# WKUP_CTRL_MMR_WKUP_CTRL_MMR_CFG0_43000000h register map
Vendor: Texas Instruments
Registers are 32-bit, read-write, reset 0x0 unless marked. A register's access mark holds for its fields unless they carry their own. Offsets are as the file gives them; [hi:lo] are bit positions; {n}, {i} and the like mark numbered series.

## WKUP_CTRL_MMR_CFG0 (part 3 of 3)
0x18440 WKUP_CTRL_MMR_CFG0_DS_DM_RESET reset 0xF
  [3:0] DS_DM_RESET_MASK — Signal used to mask main domain resets from Device Manager / Wakeup and MCU IpsField values (others are reserved):4'b0110 - Masked4'b1111 - UnMasked Reset Source: mcu_chip1_rst_n
0x18460 WKUP_CTRL_MMR_CFG0_DS_USB0_RESET reset 0xF
  [3:0] DS_USB0_RESET_MASK — Signal used to block reset to the USBSS0Field values (others are reserved):4'b0110 - Masked4'b1111 - UnMasked Reset Source: mcu_chip1_rst_n
0x18464 WKUP_CTRL_MMR_CFG0_DS_USB1_RESET reset 0xF
  [3:0] DS_USB1_RESET_MASK — Signal used to block reset to the USBSS1Field values (others are reserved):4'b0110 - Masked4'b1111 - UnMasked Reset Source: mcu_chip1_rst_n
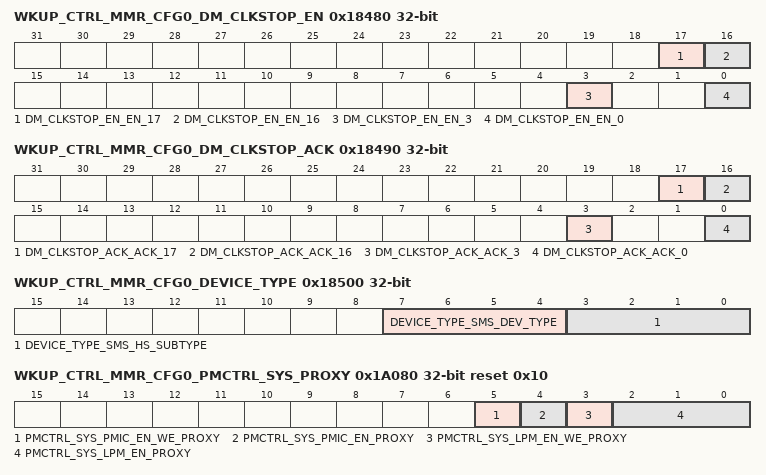
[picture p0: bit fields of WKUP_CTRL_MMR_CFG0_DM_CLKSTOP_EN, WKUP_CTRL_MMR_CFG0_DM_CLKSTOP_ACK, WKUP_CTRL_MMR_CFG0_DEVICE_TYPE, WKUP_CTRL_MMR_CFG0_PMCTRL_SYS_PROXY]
0x18480 WKUP_CTRL_MMR_CFG0_DM_CLKSTOP_EN
  [17] DM_CLKSTOP_EN_EN_17 — WKUP DMTIMER1 Participation in Clockstop Req GroupField values (others are reserved):1'b0 - Not Participating in Clockstop Override Group. DM_CLKSTOP_ACK.17 always reads '1'1'b1 - Participating in Clockstop Override Group. DM_CLKSTOP_ACK.17 reflects the IP clockstop_ack Reset Source: mod_por_rst_n
  [16] DM_CLKSTOP_EN_EN_16 — WKUP DMTIMER0 Participation in Clockstop Req GroupField values (others are reserved):1'b0 - Not Participating in Clockstop Override Group. DM_CLKSTOP_ACK.16 always reads '1'1'b1 - Participating in Clockstop Override Group. DM_CLKSTOP_ACK.16 reflects the IP clockstop_ack Reset Source: mod_por_rst_n
  [3] DM_CLKSTOP_EN_EN_3 — WKUP UART0 Participation in Clockstop Req GroupField values (others are reserved):1'b0 - Not Participating in Clockstop Override Group. DM_CLKSTOP_ACK.3 always reads '1'1'b1 - Participating in Clockstop Override Group. DM_CLKSTOP_ACK.3 reflects the IP clockstop_ack Reset Source: mod_por_rst_n
  [0] DM_CLKSTOP_EN_EN_0 — WKUP I2C0 Participation in Clockstop Req GroupField values (others are reserved):1'b0 - Not Participating in Clockstop Override Group. DM_CLKSTOP_ACK.0 always reads '1'1'b1 - Participating in Clockstop Override Group. DM_CLKSTOP_ACK.0 reflects the IP clockstop_ack Reset Source: mod_por_rst_n
0x18490 WKUP_CTRL_MMR_CFG0_DM_CLKSTOP_ACK ro
  [17] DM_CLKSTOP_ACK_ACK_17 — WKUP DMTIMER1 Clockstop Ack StatusField values (others are reserved):1'b0 - IP is Participating in Clockstop Override Group, and IP clockstop_ack is 01'b1 - IP Is either not Participating in Clockstop Override Group, or IP has returned IP clockstop_ack Reset Source: mod_por_rst_n
  [16] DM_CLKSTOP_ACK_ACK_16 — WKUP DMTIMER0 Clockstop Ack StatusField values (others are reserved):1'b0 - IP is Participating in Clockstop Override Group, and IP clockstop_ack is 01'b1 - IP Is either not Participating in Clockstop Override Group, or IP has returned IP clockstop_ack Reset Source: mod_por_rst_n
  [3] DM_CLKSTOP_ACK_ACK_3 — WKUP UART0 Clockstop Ack StatusField values (others are reserved):1'b0 - IP is Participating in Clockstop Override Group, and IP clockstop_ack is 01'b1 - IP Is either not Participating in Clockstop Override Group, or IP has returned IP clockstop_ack Reset Source: mod_por_rst_n
  [0] DM_CLKSTOP_ACK_ACK_0 — WKUP I2C0 Clockstop Ack StatusField values (others are reserved):1'b0 - IP is Participating in Clockstop Override Group, and IP clockstop_ack is 01'b1 - IP Is either not Participating in Clockstop Override Group, or IP has returned IP clockstop_ack Reset Source: mod_por_rst_n
0x184A0 WKUP_CTRL_MMR_CFG0_DM_GRP_CLKSTOP_REQ
  [0] DM_GRP_CLKSTOP_REQ_REQ — Assertion of Clockstop Req to IPs participating in Clockstop Req GroupField values (others are reserved):1'b0 - Deassert CLKSTOP Req to all IPs participating in Clockstop Override Group1'b1 - Assert CLKSTOP Req to all IPs participating in Clockstop Override Group Reset Source: mod_por_rst_n
0x184A4 WKUP_CTRL_MMR_CFG0_DM_GRP_CLKSTOP_ACK ro
  [0] DM_GRP_CLKSTOP_ACK_ACK — Status of IPs Participating in Clockstop Ack Group. If DM_CLKSTOP_EN is 0 (no IPs participating) this bit always reads 1.Field values (others are reserved):1'b0 - At least one IP participating in Clockstop Override has not returned Ack1'b1 - All IPs that are participating in Clockstop Override have returned Ack Reset Source: mod_por_rst_n
0x18500 WKUP_CTRL_MMR_CFG0_DEVICE_TYPE ro
  [7:4] DEVICE_TYPE_SMS_DEV_TYPE — Reset Source: mod_por_rst_n
  [3:0] DEVICE_TYPE_SMS_HS_SUBTYPE — this field is not needed and inputs should be tied off on AM62. Reset Source: mod_por_rst_n
{0x19100+4i} WKUP_CTRL_MMR_CFG0_CLAIMREG_P6_R{i}_READONLY ro (i=0..10)
  [31:0] CLAIMREG_P6_R{i}_READONLY — Claim bits for Partition 6 Reset Source: mod_g_rst_n
0x1A040 WKUP_CTRL_MMR_CFG0_FW_CTRL_OUT0_PROXY
  [31:0] FW_CTRL_OUT0_FW_CTRL_OUT0_PROXY — Reset Source: mod_g_rst_n
0x1A044 WKUP_CTRL_MMR_CFG0_FW_CTRL_OUT0_SET_PROXY access not given
  [31:0] FW_CTRL_OUT0_SET_FW_CTRL_OUT0_PROXY — reserved Reset Source: mod_g_rst_n (access R/W1TS)
0x1A048 WKUP_CTRL_MMR_CFG0_FW_CTRL_OUT0_CLR_PROXY access not given
  [31:0] FW_CTRL_OUT0_CLR_FW_CTRL_OUT0_PROXY — reserved Reset Source: mod_g_rst_n (access R/W1TC)
0x1A04C WKUP_CTRL_MMR_CFG0_FW_STS_IN0_PROXY ro
  [31:0] FW_STS_IN0_EVENT_PROXY — Reserved Reset Source: mod_g_rst_n
0x1A050 WKUP_CTRL_MMR_CFG0_FW_CTRL_OUT1_PROXY
  [31:0] FW_CTRL_OUT1_FW_CTRL_OUT1_PROXY — reserved Reset Source: mod_g_rst_n
0x1A054 WKUP_CTRL_MMR_CFG0_FW_CTRL_OUT1_SET_PROXY access not given
  [31:0] FW_CTRL_OUT1_SET_FW_CTRL_OUT1_PROXY — reserved Reset Source: mod_g_rst_n (access R/W1TS)
0x1A058 WKUP_CTRL_MMR_CFG0_FW_CTRL_OUT1_CLR_PROXY access not given
  [31:0] FW_CTRL_OUT1_CLR_FW_CTRL_OUT1_PROXY — reserved Reset Source: mod_g_rst_n (access R/W1TC)
0x1A05C WKUP_CTRL_MMR_CFG0_FW_STS_IN1_PROXY ro
  [31:0] FW_STS_IN1_EVENT_PROXY — Reserved Reset Source: mod_g_rst_n
0x1A080 WKUP_CTRL_MMR_CFG0_PMCTRL_SYS_PROXY reset 0x10
  [5] PMCTRL_SYS_PMIC_EN_WE_PROXY — Unused Field - Value is Don't Care Reset Source: mod_g_rst_n
  [4] PMCTRL_SYS_PMIC_EN_PROXY — Controls state of PMIC_LPM_EN_OUT when LPM_EN[2:0] is 000 Reset Source: mod_g_rst_n
  [3] PMCTRL_SYS_LPM_EN_WE_PROXY — Unused Field - Value is Don't Care Reset Source: mod_g_rst_n
  [2:0] PMCTRL_SYS_LPM_EN_PROXY — Controls whether PMIC_LPM_EN_OUT is driven by the pmic_en bit, or by deep sleep logic. Field values (others are reserved):3'b000 - PMIC_LPM_EN_OUT controlled by pmic_en bit.3'b101 - PMIC_LPM_EN_OUT controlled by DeepSleep Logic Reset Source: mod_g_rst_n
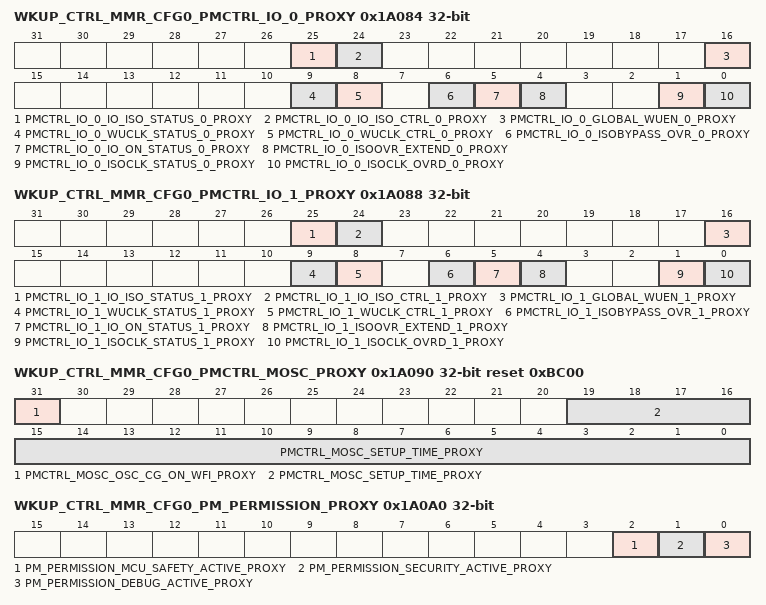
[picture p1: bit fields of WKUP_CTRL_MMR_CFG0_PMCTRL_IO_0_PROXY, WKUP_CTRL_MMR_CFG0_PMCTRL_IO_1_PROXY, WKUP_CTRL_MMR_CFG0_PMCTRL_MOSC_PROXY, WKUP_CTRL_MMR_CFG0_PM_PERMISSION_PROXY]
0x1A084 WKUP_CTRL_MMR_CFG0_PMCTRL_IO_0_PROXY access per field
  [25] PMCTRL_IO_0_IO_ISO_STATUS_0_PROXY ro — IO ISO Status. Read 0: IO isolation not active. Read 1: IO isolation active.Reflects value of DM input port io_isoack coming back fromIO pad ring. Reset Source: mod_g_rst_n
  [24] PMCTRL_IO_0_IO_ISO_CTRL_0_PROXY rw — IO ISO control. Writing this bit to 1 will kick off IO isolation. Reset Source: mod_g_rst_n
  [16] PMCTRL_IO_0_GLOBAL_WUEN_0_PROXY rw — Global IO wakeup activate. This is a gating condition to allindividual IO WUEN coming from control module. Gating isdone in the Spinner logic. 0:All individual IO WUEN are gatedin the Spinner logic (override to 0). 1: All individual IO WUENfrom control module are going to Ios.Map to DM input port io_globalwkupen Reset Source: mod_g_rst_n
  [9] PMCTRL_IO_0_WUCLK_STATUS_0_PROXY ro — Reflects value of DM input port io_wuclkack coming backfrom IO pad ring. Reset Source: mod_g_rst_n
  [8] PMCTRL_IO_0_WUCLK_CTRL_0_PROXY rw — Direct control on WUCLKIN signal to IO pad ring.0:WUCLKINsignal is driven to 0.IO wakeup daisy chain is functional as wellas IO whose wakeup feature is activated. 1:WUCLKIN signal is driven to 1. IO wakeup daisy chain is reset and is latching current pad states and WUEN inputs. Reset Source: mod_g_rst_n
  [6] PMCTRL_IO_0_ISOBYPASS_OVR_0_PROXY rw — This MMR bit drives directly DM output port io_isobypassundefined. Reset Source: mod_g_rst_n
  [5] PMCTRL_IO_0_IO_ON_STATUS_0_PROXY ro — Gives the functional status of the IO ring. Read 0: Part or all ofthe Ios are not in the ON state that is are in isolation state.Read 1: All Ios are in the ON state.io_on_status = assign 1 if (io_iso == 0 & io_isoack==0 &io_iso_clk == 0 & io_isoclk_ack = 0 ) else 0; Reset Source: mod_g_rst_n
  [4] PMCTRL_IO_0_ISOOVR_EXTEND_0_PROXY rw — This drives the SOC chain ISO-OVERRIDE global control.This bit drives directly the DM output port io_isoovrundefined. Atthe SOC level it is used to activate when 1 or gate-off when 0,the individual ISOOR for each IO. This operates as a globalactivate/deactivate for the individual IOs.Control for IO isolation extension.'0' IO isolation is not extended. Transition happens as soon asautomatic restore is completed.'1' IO isolation is extended. The IOs whose ISOOVR bits havebeen individually set in their PADCFG MMRs will all get its IOisolation extended beyond the point when the initial IO daisychain isolation is released. Reset Source: mod_g_rst_n
  [1] PMCTRL_IO_0_ISOCLK_STATUS_0_PROXY ro — Reflects value of DM input port io_isoclkack coming backfrom IO pad ring. Reset Source: mod_g_rst_n
  [0] PMCTRL_IO_0_ISOCLK_OVRD_0_PROXY rw — Override control on ISOCLKIN signal to IO pad ring.When not overridden this signal is controlled by hardware only.0 ISOCLKIN signal is not override.1 ISOCLKIN signal is overridden to active value ('1'). Reset Source: mod_g_rst_n
0x1A088 WKUP_CTRL_MMR_CFG0_PMCTRL_IO_1_PROXY access per field
  [25] PMCTRL_IO_1_IO_ISO_STATUS_1_PROXY ro — IO ISO Status. Read 0: IO isolation not active. Read 1: IO isolation active.Reflects value of DM input port io_isoack coming back fromIO pad ring. Reset Source: mod_g_rst_n
  [24] PMCTRL_IO_1_IO_ISO_CTRL_1_PROXY rw — IO ISO control. Writing this bit to 1 will kick off IO isolation. Reset Source: mod_g_rst_n
  [16] PMCTRL_IO_1_GLOBAL_WUEN_1_PROXY rw — Global IO wakeup activate. This is a gating condition to allindividual IO WUEN coming from control module. Gating isdone in the Spinner logic. 0:All individual IO WUEN are gatedin the Spinner logic (override to 0). 1: All individual IO WUENfrom control module are going to Ios.Map to DM input port io_globalwkupen Reset Source: mod_g_rst_n
  [9] PMCTRL_IO_1_WUCLK_STATUS_1_PROXY ro — Reflects value of DM input port io_wuclkack coming backfrom IO pad ring. Reset Source: mod_g_rst_n
  [8] PMCTRL_IO_1_WUCLK_CTRL_1_PROXY rw — Direct control on WUCLKIN signal to IO pad ring.0:WUCLKINsignal is driven to 0.IO wakeup daisy chain is functional as wellas IO whose wakeup feature is activated. 1:WUCLKIN signal is driven to 1. IO wakeup daisy chain is reset and is latching current pad states and WUEN inputs. Reset Source: mod_g_rst_n
  [6] PMCTRL_IO_1_ISOBYPASS_OVR_1_PROXY rw — This MMR bit drives directly DM output port io_isobypassundefined. Reset Source: mod_g_rst_n
  [5] PMCTRL_IO_1_IO_ON_STATUS_1_PROXY ro — Gives the functional status of the IO ring. Read 0: Part or all ofthe Ios are not in the ON state that is are in isolation state.Read 1: All Ios are in the ON state.io_on_status = assign 1 if (io_iso == 0 & io_isoack==0 &io_iso_clk == 0 & io_isoclk_ack = 0 ) else 0; Reset Source: mod_g_rst_n
  [4] PMCTRL_IO_1_ISOOVR_EXTEND_1_PROXY rw — This drives the SOC chain ISO-OVERRIDE global control.This bit drives directly the DM output port io_isoovrundefined. Atthe SOC level it is used to activate when 1 or gate-off when 0,the individual ISOOR for each IO. This operates as a globalactivate/deactivate for the individual IOs.Control for IO isolation extension.'0' IO isolation is not extended. Transition happens as soon asautomatic restore is completed.'1' IO isolation is extended. The IOs whose ISOOVR bits havebeen individually set in their PADCFG MMRs will all get its IOisolation extended beyond the point when the initial IO daisychain isolation is released. Reset Source: mod_g_rst_n
  [1] PMCTRL_IO_1_ISOCLK_STATUS_1_PROXY ro — Reflects value of DM input port io_isoclkack coming backfrom IO pad ring. Reset Source: mod_g_rst_n
  [0] PMCTRL_IO_1_ISOCLK_OVRD_1_PROXY rw — Override control on ISOCLKIN signal to IO pad ring.When not overridden this signal is controlled by hardware only.0 ISOCLKIN signal is not override.1 ISOCLKIN signal is overridden to active value ('1'). Reset Source: mod_g_rst_n
0x1A090 WKUP_CTRL_MMR_CFG0_PMCTRL_MOSC_PROXY reset 0xBC00
  [31] PMCTRL_MOSC_OSC_CG_ON_WFI_PROXY — When set by Device Manager - the soc clock gating logic will gate the device manager clock once Device Manager has entered the WFI state. (Note: this was named osc_cg_dis but name didn't match function) Reset Source: mod_g_rst_n
  [19:0] PMCTRL_MOSC_SETUP_TIME_PROXY — Keep the main oscillator clock gates for the number ofHFOSC clock cycles This is the time it takes to stabilizethe clock source supplier (i.e. Main Oscillator) Reset Source: mod_g_rst_n
0x1A098 WKUP_CTRL_MMR_CFG0_PM_MISC_STATUS_PROXY ro
  [1:0] PM_MISC_STATUS_OSC_CG_STAT_PROXY — Reflects the status of the request to clock-gate HFoscillator via MMR PMCTRL_MOSCundefined.11: osc_cgen_req = '0' &osc_cgen_ack = '1'10: osc_cgen_req = '1' &osc_cgen_ack = '0'01: osc_cgen_req = '0' &osc_cgen_ack = '0'00: osc_cgen_req = '1' &osc_cgen_ack = '1' Reset Source: mod_g_rst_n
0x1A09C WKUP_CTRL_MMR_CFG0_PMCTRL_IO_GLB_PROXY
  [1:0] PMCTRL_IO_GLB_DSEN_QUALIFIED_PROXY — To dsen_qualified signal generation logic for daisychain[1:0] logic. Used to control I/O buffer ouput and output activate during deepsleep mode. See IO Integration spec for detail. Reset Source: mod_g_rst_n
0x1A0A0 WKUP_CTRL_MMR_CFG0_PM_PERMISSION_PROXY ro
  [2] PM_PERMISSION_MCU_SAFETY_ACTIVE_PROXY — Read Only - Reads return a 1 when am62_mcu_ctrl_mmr.wkup_0.RST_MAGIC_WORD_mcu_magic_word_ipcfg[31:0] != 32'h0.When 1, indicates that the MCU is blocking reset and also deep sleep entry. Reset Source: mod_g_rst_n
  [1] PM_PERMISSION_SECURITY_ACTIVE_PROXY — Read Only - Reads return the value of ms.main_0.sms_iopm_pmpermission_security_active. When 1, indicates that SMS is blocking deep sleep entry. Reset Source: mod_g_rst_n
  [0] PM_PERMISSION_DEBUG_ACTIVE_PROXY — Read Only - Returns a 1 when IceMelter is blocking deep sleep entry. Reset Source: mod_g_rst_n
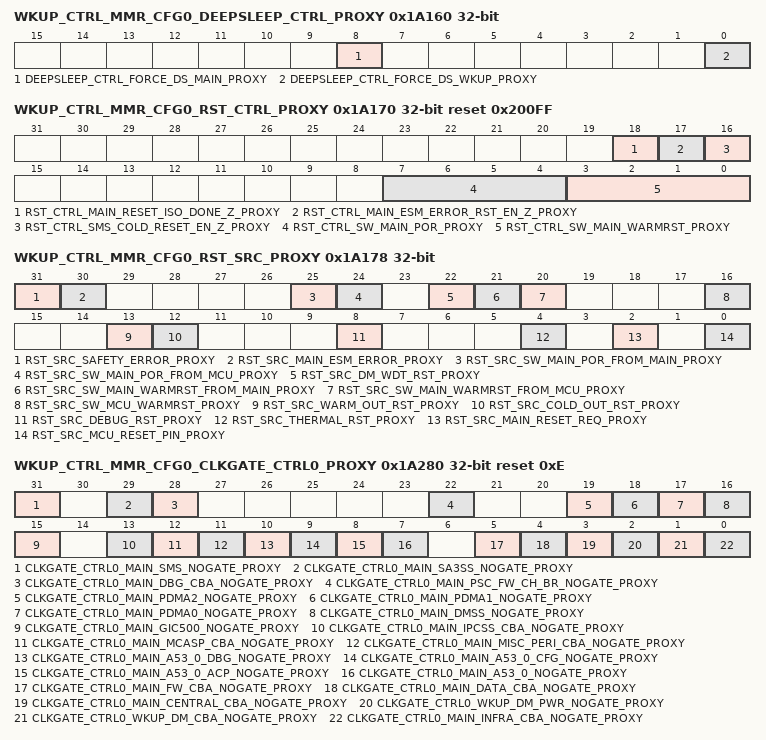
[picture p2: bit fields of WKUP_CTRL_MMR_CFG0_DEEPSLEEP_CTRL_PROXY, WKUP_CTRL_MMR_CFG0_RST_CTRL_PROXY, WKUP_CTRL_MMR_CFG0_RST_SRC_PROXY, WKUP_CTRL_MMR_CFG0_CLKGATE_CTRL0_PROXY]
0x1A160 WKUP_CTRL_MMR_CFG0_DEEPSLEEP_CTRL_PROXY
  [8] DEEPSLEEP_CTRL_FORCE_DS_MAIN_PROXY — Force all MAIN IOs into deepsleep mode when set Reset Source: mod_por_rst_n
  [0] DEEPSLEEP_CTRL_FORCE_DS_WKUP_PROXY — Force all WKUP IOs into deepsleep mode when set Reset Source: mod_por_rst_n
0x1A170 WKUP_CTRL_MMR_CFG0_RST_CTRL_PROXY reset 0x200FF
  [18] RST_CTRL_MAIN_RESET_ISO_DONE_Z_PROXY — Main Domain CPUs can set this bit to block warm reset in the main domain which is useful when the Main domain may be accessing main domain resources (peripherals, memory..). In this case, the main domain cpus will be notified via an interrupt that there is an outstanding warm reset request for the main domain. Once notified, Main needs to finish any outstanding operations in has with main domain resources and then clear this bit. After this bit is cleared, the main domain warm reset will unblocked and the warm reset sequence may continue. 0 - Reset of Main Domain is not Blocked by Main Domain 1 - Reset of Main Domain is Blocked by Main Domain Reset Source: main_chip1_rst_n
  [17] RST_CTRL_MAIN_ESM_ERROR_RST_EN_Z_PROXY — Deactivate Reset of Main by ESM 0 - Activated 1 - Deactivated Reset Source: main_chip1_rst_n
  [16] RST_CTRL_SMS_COLD_RESET_EN_Z_PROXY — Deactivate Reset of Main by SMS 0 - Activated 1 - Deactivated Reset Source: main_chip1_rst_n
  [7:4] RST_CTRL_SW_MAIN_POR_PROXY — Causes Main Domain Power On Reset when set to 4'b0110, Bits will reset to 4'b1111 Reset Source: main_chip1_rst_n
  [3:0] RST_CTRL_SW_MAIN_WARMRST_PROXY — Causes Main Domain Warm Reset when set to 4'b0110, Bits will reset to 4'b1111 Reset Source: main_chip1_rst_n
0x1A174 WKUP_CTRL_MMR_CFG0_RST_STAT_PROXY ro
  [0] RST_STAT_MCU_RESET_ISO_DONE_Z_PROXY — is an outstanding warm reset request for the main domain. Once notified, MCU needs to finish any outstanding Reset Source: main_chip1_rst_n
0x1A178 WKUP_CTRL_MMR_CFG0_RST_SRC_PROXY ro
  [31] RST_SRC_SAFETY_ERROR_PROXY — Reset Caused by MCU ESM Error Reset Source: main_chip1_rst_n
  [30] RST_SRC_MAIN_ESM_ERROR_PROXY — Reset Caused by Main ESM Error Reset Source: main_chip1_rst_n
  [25] RST_SRC_SW_MAIN_POR_FROM_MAIN_PROXY — Software Main Power On Reset From MAIN CTRL MMR Reset Source: main_chip1_rst_n
  [24] RST_SRC_SW_MAIN_POR_FROM_MCU_PROXY — Software Main Power On Reset From MCU CTRL MMR Reset Source: main_chip1_rst_n
  [22] RST_SRC_DM_WDT_RST_PROXY — Watchdog Initiated Reset Reset Source: main_chip1_rst_n
  [21] RST_SRC_SW_MAIN_WARMRST_FROM_MAIN_PROXY — Software Main Warm Reset from MAIN CTRL MMR Reset Source: main_chip1_rst_n
  [20] RST_SRC_SW_MAIN_WARMRST_FROM_MCU_PROXY — Software Main Warm Reset From MCU CTRL MMR Reset Source: main_chip1_rst_n
  [16] RST_SRC_SW_MCU_WARMRST_PROXY — Software Warm Reset Reset Source: main_chip1_rst_n
  [13] RST_SRC_WARM_OUT_RST_PROXY — SMS Warm Reset Reset Source: main_chip1_rst_n
  [12] RST_SRC_COLD_OUT_RST_PROXY — SMS Cold Reset Reset Source: main_chip1_rst_n
  [8] RST_SRC_DEBUG_RST_PROXY — Debug Subsystem Initiated Reset Reset Source: main_chip1_rst_n
  [4] RST_SRC_THERMAL_RST_PROXY — Thermal Reset Reset Source: main_chip1_rst_n
  [2] RST_SRC_MAIN_RESET_REQ_PROXY — Main Reset Pin Reset Source: main_chip1_rst_n
  [0] RST_SRC_MCU_RESET_PIN_PROXY — Rest Caused by MCU Reset Pin Reset Source: main_chip1_rst_n
0x1A17C WKUP_CTRL_MMR_CFG0_RST_MAGIC_WORD_PROXY ro
  [31:0] RST_MAGIC_WORD_MCU_MAGIC_WORD_PROXY — Magic Word Indicating Status of MCU Subsystem Boot Reset Source: main_chip1_rst_n
0x1A180 WKUP_CTRL_MMR_CFG0_WKUP0_EN_PROXY
  [31:0] WKUP0_EN_WKUPEN_PROXY — Activates Wakeup from: b0 - WKUP I2C0 b1 - WKUP USART0 b2 - MCU GPIO0 b3 - DEBUG (IceMelter) b4 - Reserved b5 - WKUP DMTIMER0 b6 - WKUP DMTIMER1 b7 - WKUP RTC b8 - Main RESET_REQz b9 - USB0 In Band b10 - USB1 In Band b16 - MAIN IO Daisy Chain b17 - MCU IO Daisy Chain b18 - CANUART IO Daisy Chain Reset Source: mod_g_rst_n
0x1A280 WKUP_CTRL_MMR_CFG0_CLKGATE_CTRL0_PROXY reset 0xE
  [31] CLKGATE_CTRL0_MAIN_SMS_NOGATE_PROXY — MAIN domain SMS (pwr_dis_nogate) clock gate deactivate. 0 - Clocks are gated on idle for power savings 1 - Clocks are not gated on idle, power saving deactivated Reset Source: mod_por_rst_n
  [29] CLKGATE_CTRL0_MAIN_SA3SS_NOGATE_PROXY — MAIN domain SA3SS clock gate deactivate. 0 - Clocks are gated on idle for power savings 1 - Clocks are not gated on idle, power saving deactivated Reset Source: mod_por_rst_n
  [28] CLKGATE_CTRL0_MAIN_DBG_CBA_NOGATE_PROXY — MAIN domain Debug CBA (main_dbg_cba)clock gate deactivate. 0 - Clocks are gated on idle for power savings 1 - Clocks are not gated on idle, power saving deactivated Reset Source: mod_por_rst_n
  [22] CLKGATE_CTRL0_MAIN_PSC_FW_CH_BR_NOGATE_PROXY — (Non-Functional) MAIN domain (psc_fw_ch_br_nogate) 0 - Clocks are gated on idle for power savings 1 - Clocks are not gated on idle, power saving deactivated Reset Source: mod_por_rst_n
  [19] CLKGATE_CTRL0_MAIN_PDMA2_NOGATE_PROXY — MAIN domain PDMA2 (pwr_dis_nogate) clock gate deactivate. 0 - Clocks are gated on idle for power savings 1 - Clocks are not gated on idle, power saving deactivated Reset Source: mod_por_rst_n
  [18] CLKGATE_CTRL0_MAIN_PDMA1_NOGATE_PROXY — MAIN domain PDMA1 (pwr_dis_nogate) clock gate deactivate. 0 - Clocks are gated on idle for power savings 1 - Clocks are not gated on idle, power saving deactivated Reset Source: mod_por_rst_n
  [17] CLKGATE_CTRL0_MAIN_PDMA0_NOGATE_PROXY — MAIN domain PDMA0 (pwr_dis_nogate) clock gate deactivate. 0 - Clocks are gated on idle for power savings 1 - Clocks are not gated on idle, power saving deactivated Reset Source: mod_por_rst_n
  [16] CLKGATE_CTRL0_MAIN_DMSS_NOGATE_PROXY — MAIN domain DMSS (pwr_dis_nogate) clock gate deactivate. 0 - Clocks are gated on idle for power savings 1 - Clocks are not gated on idle, power saving deactivated Reset Source: mod_por_rst_n
  [15] CLKGATE_CTRL0_MAIN_GIC500_NOGATE_PROXY — MAIN A53SS0 (gic500_1_2) clock gate deactivate. 0 - Clocks are gated on idle for power savings 1 - Clocks are not gated on idle, power saving deactivated Reset Source: mod_por_rst_n
  [13] CLKGATE_CTRL0_MAIN_IPCSS_CBA_NOGATE_PROXY — MAIN domain Infrastructure bus (main_ipcss_cbass) clock gate deactivate. 0 - Clocks are gated on idle for power savings 1 - Clocks are not gated on idle, power saving deactivated Reset Source: mod_por_rst_n
  [12] CLKGATE_CTRL0_MAIN_MCASP_CBA_NOGATE_PROXY — MAIN domain Infrastructure bus (main_mcasp_cbass) clock gate deactivate. 0 - Clocks are gated on idle for power savings 1 - Clocks are not gated on idle, power saving deactivated Reset Source: mod_por_rst_n
  [11] CLKGATE_CTRL0_MAIN_MISC_PERI_CBA_NOGATE_PROXY — MAIN domain Infrastructure bus (main_misc_peri_cbass) clock gate deactivate. 0 - Clocks are gated on idle for power savings 1 - Clocks are not gated on idle, power saving deactivated Reset Source: mod_por_rst_n
  [10] CLKGATE_CTRL0_MAIN_A53_0_DBG_NOGATE_PROXY — MAIN A53SS0 Debug Port clock gate deactivate. 0 - Clocks are gated on idle for power savings 1 - Clocks are not gated on idle, power saving deactivated Reset Source: mod_por_rst_n
  [9] CLKGATE_CTRL0_MAIN_A53_0_CFG_NOGATE_PROXY — MAIN A53SS0 Configuration Port clock gate deactivate. 0 - Clocks are gated on idle for power savings 1 - Clocks are not gated on idle, power saving deactivated Reset Source: mod_por_rst_n
  [8] CLKGATE_CTRL0_MAIN_A53_0_ACP_NOGATE_PROXY — MAIN A53SS0 ACP clock gate deactivate. 0 - Clocks are gated on idle for power savings 1 - Clocks are not gated on idle, power saving deactivated Reset Source: mod_por_rst_n
  [7] CLKGATE_CTRL0_MAIN_A53_0_NOGATE_PROXY — MAIN A53SS0 clock gate deactivate. 0 - Clocks are gated on idle for power savings 1 - Clocks are not gated on idle, power saving deactivated Reset Source: mod_por_rst_n
  [5] CLKGATE_CTRL0_MAIN_FW_CBA_NOGATE_PROXY — MAIN domain datal bus (main_fw_cbass) clock gate deactivate. 0 - Clocks are gated on idle for power savings 1 - Clocks are not gated on idle, power saving deactivated Reset Source: mod_por_rst_n
  [4] CLKGATE_CTRL0_MAIN_DATA_CBA_NOGATE_PROXY — MAIN domain data bus (main_cbass) clock gate deactivate. 0 - Clocks are gated on idle for power savings 1 - Clocks are not gated on idle, power saving deactivated Reset Source: mod_por_rst_n
  [3] CLKGATE_CTRL0_MAIN_CENTRAL_CBA_NOGATE_PROXY — WKUP domain Infrastructure ECC aggregator(wkup_safe_ecc_aggr) clock gate deactivate. 0 - Clocks are gated on idle for power savings 1 - Clocks are not gated on idle, power saving deactivated Reset Source: mod_por_rst_n
  [2] CLKGATE_CTRL0_WKUP_DM_PWR_NOGATE_PROXY — WKUP domain Device Manager (wkup_dm_pwr_nogate) clock gate deactivate. 0 - Clocks are gated on idle for power savings 1 - Clocks are not gated on idle, power saving deactivated Reset Source: mod_por_rst_n
  [1] CLKGATE_CTRL0_WKUP_DM_CBA_NOGATE_PROXY — WKUP domain device manager CBA clock gate deactivate. 0 - Clocks are gated on idle for power savings 1 - Clocks are not gated on idle, power saving deactivated Reset Source: mod_por_rst_n
  [0] CLKGATE_CTRL0_MAIN_INFRA_CBA_NOGATE_PROXY — MAIN domain Infrastructure bus (main_infra_cbass and psc_fw_ch_br) clock gate deactivate. 0 - Clocks are gated on idle for power savings 1 - Clocks are not gated on idle, power saving deactivated Reset Source: mod_por_rst_n
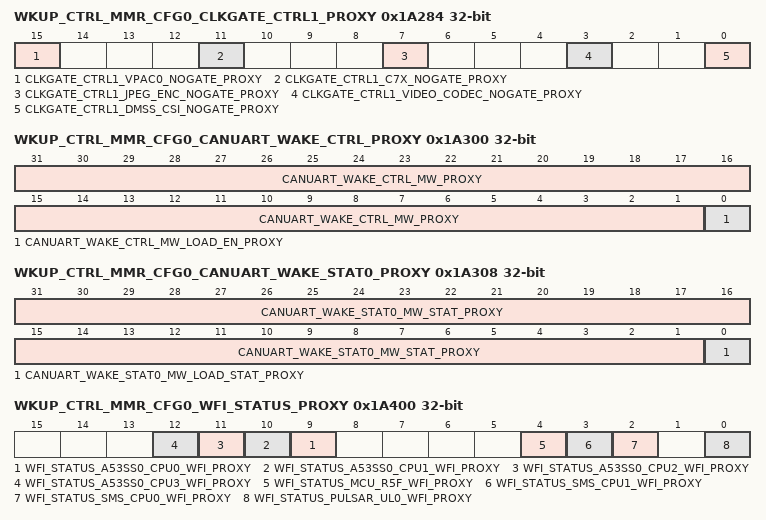
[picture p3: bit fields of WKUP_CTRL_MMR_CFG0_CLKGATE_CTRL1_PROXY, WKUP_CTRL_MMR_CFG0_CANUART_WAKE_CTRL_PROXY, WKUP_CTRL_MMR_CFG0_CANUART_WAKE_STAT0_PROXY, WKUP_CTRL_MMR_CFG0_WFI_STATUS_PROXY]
0x1A284 WKUP_CTRL_MMR_CFG0_CLKGATE_CTRL1_PROXY
  [15] CLKGATE_CTRL1_VPAC0_NOGATE_PROXY — VPAC0 clock gate deactivate. 0 - Clocks are gated on idle for power savings 1 - Clocks are not gated on idle, power saving deactivated Reset Source: mod_por_rst_n
  [11] CLKGATE_CTRL1_C7X_NOGATE_PROXY — C7x clock gate deactivate. 0 - Clocks are gated on idle for power savings 1 - Clocks are not gated on idle, power saving deactivated Reset Source: mod_por_rst_n
  [7] CLKGATE_CTRL1_JPEG_ENC_NOGATE_PROXY — JPEG Encoder clock gate deactivate. 0 - Clocks are gated on idle for power savings 1 - Clocks are not gated on idle, power saving deactivated Reset Source: mod_por_rst_n
  [3] CLKGATE_CTRL1_VIDEO_CODEC_NOGATE_PROXY — VIDEO CODEC clock gate deactivate. 0 - Clocks are gated on idle for power savings 1 - Clocks are not gated on idle, power saving deactivated Reset Source: mod_por_rst_n
  [0] CLKGATE_CTRL1_DMSS_CSI_NOGATE_PROXY — DMSS_CSI clock gate deactivate. 0 - Clocks are gated on idle for power savings 1 - Clocks are not gated on idle, power saving deactivated Reset Source: mod_por_rst_n
0x1A300 WKUP_CTRL_MMR_CFG0_CANUART_WAKE_CTRL_PROXY
  [31:1] CANUART_WAKE_CTRL_MW_PROXY — CANUART IO magic word. This 31-bit value that activates placing of the CANUART I/Os into isolation for daisy-chain wakeup operation. The Upper 8 bits are software defined. The lower 23 bits are checked by hardware:- 0x5AAAAA - Magic word value to activate isolation whenqualified with mw_load bit- Others - Any other value will prevent isolation when mw_loadtransitions from 0 to 1 Reset Source: mcu_chip1_rst_n
  [0] CANUART_WAKE_CTRL_MW_LOAD_EN_PROXY — Magic word load activateSetting this bit to 1 loads and locks the mw field for CANUART IO isolation. If the mw field matches the magicword value then the value is latched into the CANUART IOvoltage domain and CANUART IO isolation is activated.0 - Unlock and do not load mw value for comparison1 - Load and lock mw for magic word value comparison Reset Source: mcu_chip1_rst_n
0x1A308 WKUP_CTRL_MMR_CFG0_CANUART_WAKE_STAT0_PROXY ro
  [31:1] CANUART_WAKE_STAT0_MW_STAT_PROXY — CANUART magic word statusIndicates the latched value of the mw field. Reset Source: mod_por_rst_n
  [0] CANUART_WAKE_STAT0_MW_LOAD_STAT_PROXY — Magic word load status.Indicates the latched value of the mw_load_en bit Reset Source: mod_por_rst_n
0x1A30C WKUP_CTRL_MMR_CFG0_CANUART_WAKE_STAT1_PROXY ro
  [0] CANUART_WAKE_STAT1_CANUART_IO_MODE_PROXY — Indicates if CANUART IO wakeup mode is activated.0 - Not activated (load_en not set or mw doesn't match magic word)1 - CANUART IO mode activated Reset Source: mod_por_rst_n
0x1A310 WKUP_CTRL_MMR_CFG0_CANUART_WAKE_OFF_MODE_PROXY
  [31:0] CANUART_WAKE_OFF_MODE_MW_PROXY — magic word Reset Source: mod_por_rst_n
0x1A318 WKUP_CTRL_MMR_CFG0_CANUART_WAKE_OFF_MODE_STAT_PROXY ro
  [31:0] CANUART_WAKE_OFF_MODE_STAT_MW_PROXY — returned magic word Reset Source: mod_por_rst_n
0x1A320 WKUP_CTRL_MMR_CFG0_CANUART_WAKE_RESUME_KEY_PROXY_j
  [31:0] KEYVAL_PROXY — key value Reset Source: mod_por_rst_n
0x1A340 WKUP_CTRL_MMR_CFG0_CANUART_WAKE_RESUME_KEY_STAT_PROXY_j ro
  [31:0] KEYVAL_PROXY — returned key value Reset Source: mod_por_rst_n
0x1A400 WKUP_CTRL_MMR_CFG0_WFI_STATUS_PROXY ro
  [n+9] WFI_STATUS_A53SS0_CPU{n}_WFI_PROXY (n=0..3) — WFI status of A53SS0 CPU{n} Reset Source: mod_por_rst_n
  [4] WFI_STATUS_MCU_R5F_WFI_PROXY — WFI status of MCU Cortex R5F Reset Source: mod_por_rst_n
  [3] WFI_STATUS_SMS_CPU1_WFI_PROXY — WFI status of SMS Cortex M4F1 Reset Source: mod_por_rst_n
  [2] WFI_STATUS_SMS_CPU0_WFI_PROXY — WFI status of SMS Cortex M4F0 Reset Source: mod_por_rst_n
  [0] WFI_STATUS_PULSAR_UL0_WFI_PROXY — WFI status of Device Manager Cortex R5F Reset Source: mod_por_rst_n
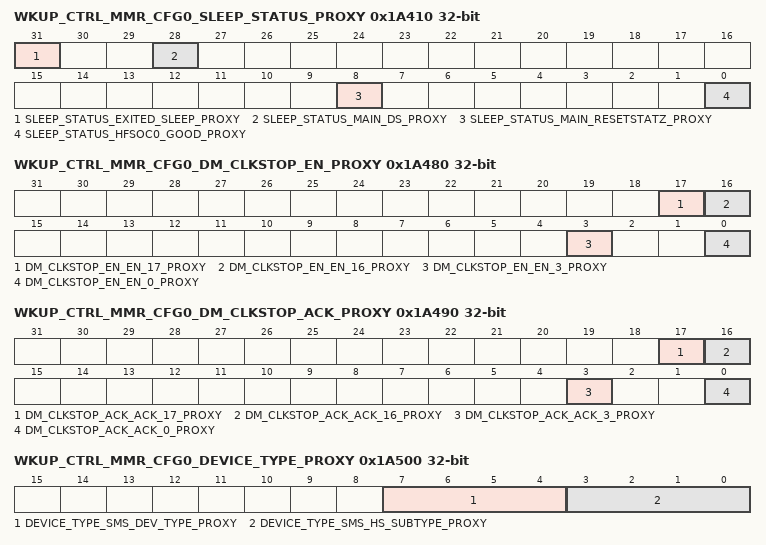
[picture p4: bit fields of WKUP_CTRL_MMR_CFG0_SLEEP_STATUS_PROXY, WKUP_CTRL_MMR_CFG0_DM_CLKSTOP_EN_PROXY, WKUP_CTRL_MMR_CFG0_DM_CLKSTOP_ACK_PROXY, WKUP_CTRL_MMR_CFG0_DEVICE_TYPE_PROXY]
0x1A410 WKUP_CTRL_MMR_CFG0_SLEEP_STATUS_PROXY access not given
  [31] SLEEP_STATUS_EXITED_SLEEP_PROXY — Set when the HFXOSC clock gate is activated (rising edge capture of OSC_CG_ACK). To be read and cleared by DM after exiting WFI as a status signal distinguishing the case where WFI was entered and the clock was stopped, then exited with a wakeup (this bit will be set) from the case where an interrupt or other event caused the WFI sequence to stop and the HFXOSC was never stopped. Reset Source: sys_por_rst_n (access R/W1TC)
  [28] SLEEP_STATUS_MAIN_DS_PROXY — Set when the main domain deep sleep power on reset / power domain off is activated. (rising edge detect of am62_wkup_ctrl_mmr.wkup_0.DS_MAIN_por_pdoff_ft_out_ipcfg). This will be checked by the ROM on TIFS upon exiting from reset to determine if it is a power on reset or exiting deep sleep. Reset Source: sys_por_rst_n (access R/W1TC)
  [8] SLEEP_STATUS_MAIN_RESETSTATZ_PROXY ro — Reflects the status of the main domain resetz signalField values (others are reserved):1'b0 - Main Domain In Reset1'b1 - Main Domain Out of Reset Reset Source: mod_g_rst_n
  [0] SLEEP_STATUS_HFSOC0_GOOD_PROXY ro — Reserved Reset Source: mod_g_rst_n
0x1A418 WKUP_CTRL_MMR_CFG0_DS_MAGIC_WORD_PROXY
  [31:0] DS_MAGIC_WORD_DS_MAGIC_WORD_PROXY — Magic Word Indicating State of Deep Sleep Reset Source: main_chip1_rst_n
0x1A420 WKUP_CTRL_MMR_CFG0_DS_MAIN_PROXY reset 0xF
  [3:0] DS_MAIN_POR_PDOFF_PROXY — Signal Puts main SMS, DebugSS and MainIP Power Domains into Power Off state, and asserts Main Power On Reset.Field values (others are reserved):4'b0110 - Off4'b1111 - On Reset Source: mcu_chip1_rst_n
0x1A440 WKUP_CTRL_MMR_CFG0_DS_DM_RESET_PROXY reset 0xF
  [3:0] DS_DM_RESET_MASK_PROXY — Signal used to mask main domain resets from Device Manager / Wakeup and MCU IpsField values (others are reserved):4'b0110 - Masked4'b1111 - UnMasked Reset Source: mcu_chip1_rst_n
0x1A460 WKUP_CTRL_MMR_CFG0_DS_USB0_RESET_PROXY reset 0xF
  [3:0] DS_USB0_RESET_MASK_PROXY — Signal used to block reset to the USBSS0Field values (others are reserved):4'b0110 - Masked4'b1111 - UnMasked Reset Source: mcu_chip1_rst_n
0x1A464 WKUP_CTRL_MMR_CFG0_DS_USB1_RESET_PROXY reset 0xF
  [3:0] DS_USB1_RESET_MASK_PROXY — Signal used to block reset to the USBSS1Field values (others are reserved):4'b0110 - Masked4'b1111 - UnMasked Reset Source: mcu_chip1_rst_n
0x1A480 WKUP_CTRL_MMR_CFG0_DM_CLKSTOP_EN_PROXY
  [17] DM_CLKSTOP_EN_EN_17_PROXY — WKUP DMTIMER1 Participation in Clockstop Req GroupField values (others are reserved):1'b0 - Not Participating in Clockstop Override Group. DM_CLKSTOP_ACK.17 always reads '1'1'b1 - Participating in Clockstop Override Group. DM_CLKSTOP_ACK.17 reflects the IP clockstop_ack Reset Source: mod_por_rst_n
  [16] DM_CLKSTOP_EN_EN_16_PROXY — WKUP DMTIMER0 Participation in Clockstop Req GroupField values (others are reserved):1'b0 - Not Participating in Clockstop Override Group. DM_CLKSTOP_ACK.16 always reads '1'1'b1 - Participating in Clockstop Override Group. DM_CLKSTOP_ACK.16 reflects the IP clockstop_ack Reset Source: mod_por_rst_n
  [3] DM_CLKSTOP_EN_EN_3_PROXY — WKUP UART0 Participation in Clockstop Req GroupField values (others are reserved):1'b0 - Not Participating in Clockstop Override Group. DM_CLKSTOP_ACK.3 always reads '1'1'b1 - Participating in Clockstop Override Group. DM_CLKSTOP_ACK.3 reflects the IP clockstop_ack Reset Source: mod_por_rst_n
  [0] DM_CLKSTOP_EN_EN_0_PROXY — WKUP I2C0 Participation in Clockstop Req GroupField values (others are reserved):1'b0 - Not Participating in Clockstop Override Group. DM_CLKSTOP_ACK.0 always reads '1'1'b1 - Participating in Clockstop Override Group. DM_CLKSTOP_ACK.0 reflects the IP clockstop_ack Reset Source: mod_por_rst_n
0x1A490 WKUP_CTRL_MMR_CFG0_DM_CLKSTOP_ACK_PROXY ro
  [17] DM_CLKSTOP_ACK_ACK_17_PROXY — WKUP DMTIMER1 Clockstop Ack StatusField values (others are reserved):1'b0 - IP is Participating in Clockstop Override Group, and IP clockstop_ack is 01'b1 - IP Is either not Participating in Clockstop Override Group, or IP has returned IP clockstop_ack Reset Source: mod_por_rst_n
  [16] DM_CLKSTOP_ACK_ACK_16_PROXY — WKUP DMTIMER0 Clockstop Ack StatusField values (others are reserved):1'b0 - IP is Participating in Clockstop Override Group, and IP clockstop_ack is 01'b1 - IP Is either not Participating in Clockstop Override Group, or IP has returned IP clockstop_ack Reset Source: mod_por_rst_n
  [3] DM_CLKSTOP_ACK_ACK_3_PROXY — WKUP UART0 Clockstop Ack StatusField values (others are reserved):1'b0 - IP is Participating in Clockstop Override Group, and IP clockstop_ack is 01'b1 - IP Is either not Participating in Clockstop Override Group, or IP has returned IP clockstop_ack Reset Source: mod_por_rst_n
  [0] DM_CLKSTOP_ACK_ACK_0_PROXY — WKUP I2C0 Clockstop Ack StatusField values (others are reserved):1'b0 - IP is Participating in Clockstop Override Group, and IP clockstop_ack is 01'b1 - IP Is either not Participating in Clockstop Override Group, or IP has returned IP clockstop_ack Reset Source: mod_por_rst_n
0x1A4A0 WKUP_CTRL_MMR_CFG0_DM_GRP_CLKSTOP_REQ_PROXY
  [0] DM_GRP_CLKSTOP_REQ_REQ_PROXY — Assertion of Clockstop Req to IPs participating in Clockstop Req GroupField values (others are reserved):1'b0 - Deassert CLKSTOP Req to all IPs participating in Clockstop Override Group1'b1 - Assert CLKSTOP Req to all IPs participating in Clockstop Override Group Reset Source: mod_por_rst_n
0x1A4A4 WKUP_CTRL_MMR_CFG0_DM_GRP_CLKSTOP_ACK_PROXY ro
  [0] DM_GRP_CLKSTOP_ACK_ACK_PROXY — Status of IPs Participating in Clockstop Ack Group. If DM_CLKSTOP_EN is 0 (no IPs participating) this bit always reads 1.Field values (others are reserved):1'b0 - At least one IP participating in Clockstop Override has not returned Ack1'b1 - All IPs that are participating in Clockstop Override have returned Ack Reset Source: mod_por_rst_n
0x1A500 WKUP_CTRL_MMR_CFG0_DEVICE_TYPE_PROXY ro
  [7:4] DEVICE_TYPE_SMS_DEV_TYPE_PROXY — Reset Source: mod_por_rst_n
  [3:0] DEVICE_TYPE_SMS_HS_SUBTYPE_PROXY — this field is not needed and inputs should be tied off on AM62. Reset Source: mod_por_rst_n
{0x1B100+4i} WKUP_CTRL_MMR_CFG0_CLAIMREG_P6_R{i} (i=0..10)
  [31:0] CLAIMREG_P6_R{i} — Claim bits for Partition 6 Reset Source: mod_g_rst_n
0x1C100 WKUP_CTRL_MMR_CFG0_BACKUP_REG_j
  [31:0] BACKUP_DATA — Storage for Backup Data During Deep Sleep Reset Source: mod_por_rst_n
{0x1D100+4i} WKUP_CTRL_MMR_CFG0_CLAIMREG_P7_R{i}_READONLY ro (i=0..2)
  [31:0] CLAIMREG_P7_R{i}_READONLY — Claim bits for Partition 7 Reset Source: mod_g_rst_n
0x1E100 WKUP_CTRL_MMR_CFG0_BACKUP_REG_PROXY_j
  [31:0] BACKUP_DATA_PROXY — Storage for Backup Data During Deep Sleep Reset Source: mod_por_rst_n
{0x1F100+4i} WKUP_CTRL_MMR_CFG0_CLAIMREG_P7_R{i} (i=0..2)
  [31:0] CLAIMREG_P7_R{i} — Claim bits for Partition 7 Reset Source: mod_g_rst_n
